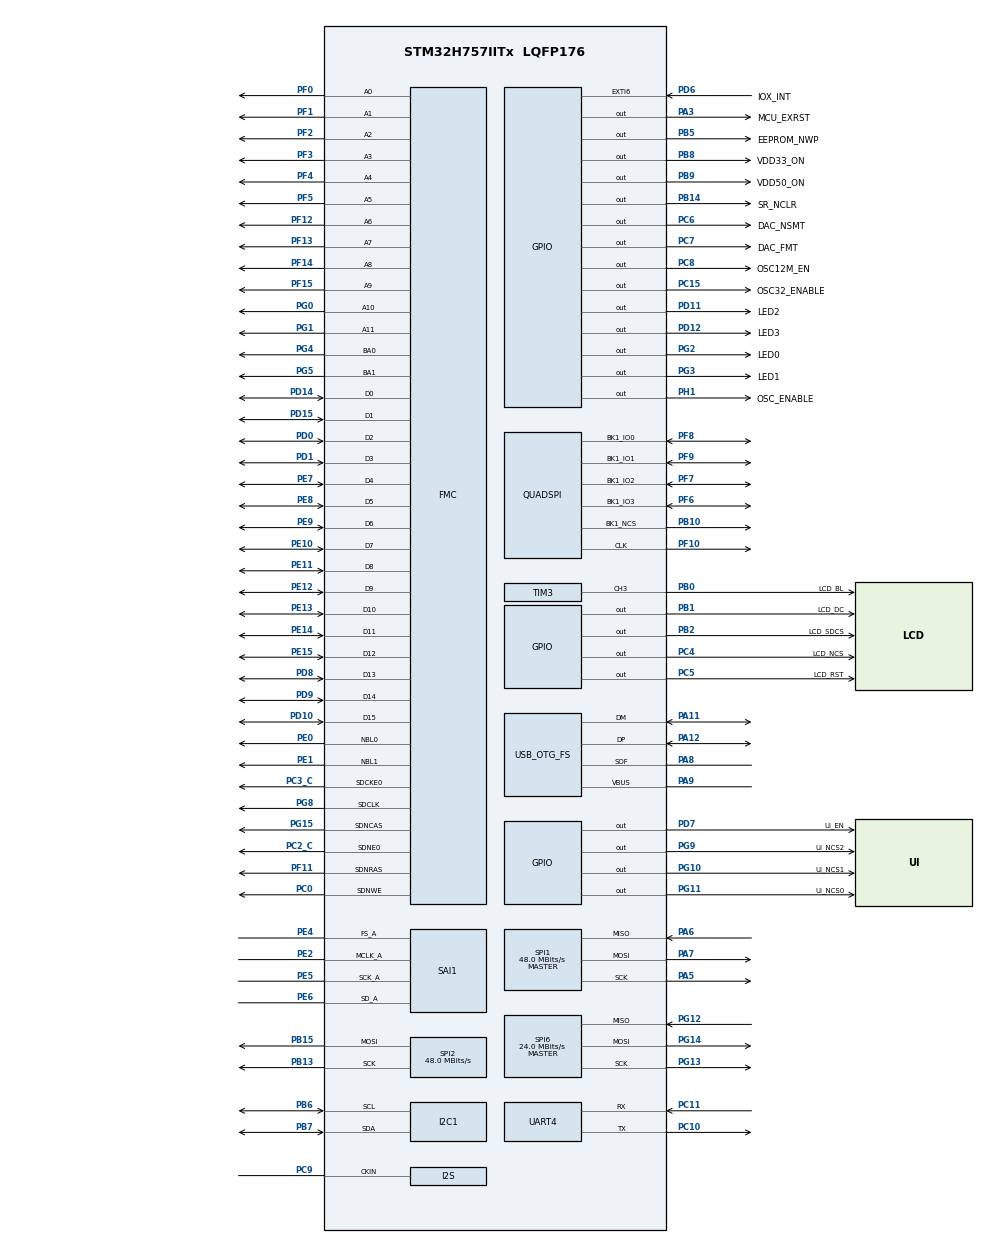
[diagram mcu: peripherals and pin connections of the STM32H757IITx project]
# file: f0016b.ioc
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CORTEX_M7.default_mode_Activation=1
CortexM4.IPs=CORTEX_M4\:I,FATFS_M4\:I,FREERTOS_M4\:I,IWDG2\:I,OPENAMP_M4\:I,PDM2PCM_M4\:I,PWR,RCC,RESMGR_UTILITY,SYS_M4\:I,USB_DEVICE_M4\:I,USB_HOST_M4\:I,VREFBUF,WWDG2\:I,GPIO,DMA,BDMA,MDMA,NVIC2\:I,DEBUG,FMC,QUADSPI
CortexM7.IPs=CORTEX_M7\:I,FATFS_M7\:I,FREERTOS_M7\:I,IWDG1\:I,OPENAMP_M7\:I,PDM2PCM_M7\:I,PWR\:I,RCC\:I,RESMGR_UTILITY\:I,SYS\:I,USB_DEVICE_M7\:I,USB_HOST_M7\:I,VREFBUF\:I,WWDG1\:I,GPIO\:I,DMA\:I,BDMA\:I,MDMA\:I,NVIC1\:I,FMC\:I,DEBUG\:I,QUADSPI\:I,USB_OTG_FS\:I,USB_OTG_FS1\:I,SPI1\:I,I2C1\:I,SAI1\:I,UART5\:I,UART4\:I,SPI6\:I,SPI2\:I,TIM3\:I
CortexM7.Pins=PC15-OSC32_OUT (OSC32_OUT),PH1-OSC_OUT (PH1),PA3,PC4,PC5,PB1,PB2,PB14,PD11,PD12,PG2,PG3,PC6,PC7,PC8,PD6,PD7,PG9,PG10,PG11,PB5,PB8,PB9
FMC.ColumnBitsNumber1=FMC_SDRAM_COLUMN_BITS_NUM_8
FMC.WriteProtection1=FMC_SDRAM_WRITE_PROTECTION_DISABLE
I2C1.Timing=0x00506682
Mcu.Family=STM32H7
Mcu.Name=STM32H757IITx
Mcu.Package=LQFP176
NVIC1.PriorityGroup=NVIC_PRIORITYGROUP_4
NVIC2.PriorityGroup=NVIC_PRIORITYGROUP_4
PA11.Mode=Device_Only
PA11.PinAttribute=CortexM7
PA11.Signal=USB_OTG_FS_DM
PA12.Mode=Device_Only
PA12.PinAttribute=CortexM7
PA12.Signal=USB_OTG_FS_DP
PA13\ (JTMS/SWDIO).Mode=Trace_Asynchronous_SW
PA13\ (JTMS/SWDIO).PinAttribute=CortexM7
PA13\ (JTMS/SWDIO).Signal=DEBUG_JTMS-SWDIO
PA14\ (JTCK/SWCLK).Mode=Trace_Asynchronous_SW
PA14\ (JTCK/SWCLK).PinAttribute=CortexM7
PA14\ (JTCK/SWCLK).Signal=DEBUG_JTCK-SWCLK
PA3.GPIO_Label=MCU_EXRST
PA3.GPIO_ModeDefaultOutputPP=GPIO_MODE_OUTPUT_OD
PA3.GPIO_PuPd=GPIO_NOPULL
PA3.PinAttribute=CortexM7
PA3.PinState=GPIO_PIN_SET
PA3.Signal=GPIO_Output
PA5.Mode=Full_Duplex_Master
PA5.PinAttribute=CortexM7
PA5.Signal=SPI1_SCK
PA6.Mode=Full_Duplex_Master
PA6.PinAttribute=CortexM7
PA6.Signal=SPI1_MISO
PA7.Mode=Full_Duplex_Master
PA7.PinAttribute=CortexM7
PA7.Signal=SPI1_MOSI
PA8.Mode=Activate_SOF_FS
PA8.PinAttribute=CortexM7
PA8.Signal=USB_OTG_FS_SOF
PA9.Mode=Activate_VBUS
PA9.PinAttribute=CortexM7
PA9.Signal=USB_OTG_FS_VBUS
PB0.GPIO_Label=LCD_BL
PB0.GPIO_ModeDefaultPP=GPIO_MODE_AF_OD
PB0.PinAttribute=CortexM7
PB0.Signal=S_TIM3_CH3
PB1.GPIO_Label=LCD_DC
PB1.PinAttribute=CortexM7
PB1.Signal=GPIO_Output
PB10.Mode=Single Bank 1
PB10.PinAttribute=CortexM7
PB10.Signal=QUADSPI_BK1_NCS
PB13.Mode=TX_Only_Simplex_Unidirect_Master
PB13.PinAttribute=CortexM7
PB13.Signal=SPI2_SCK
PB14.GPIO_Label=SR_NCLR
PB14.GPIO_ModeDefaultOutputPP=GPIO_MODE_OUTPUT_OD
PB14.GPIO_PuPd=GPIO_NOPULL
PB14.PinAttribute=CortexM7
PB14.PinState=GPIO_PIN_SET
PB14.Signal=GPIO_Output
PB15.Mode=TX_Only_Simplex_Unidirect_Master
PB15.PinAttribute=CortexM7
PB15.Signal=SPI2_MOSI
PB2.GPIO_Label=LCD_SDCS
PB2.GPIO_ModeDefaultOutputPP=GPIO_MODE_OUTPUT_OD
PB2.GPIO_PuPd=GPIO_NOPULL
PB2.PinAttribute=CortexM7
PB2.PinState=GPIO_PIN_SET
PB2.Signal=GPIO_Output
PB3\ (JTDO/TRACESWO).Mode=Trace_Asynchronous_SW
PB3\ (JTDO/TRACESWO).PinAttribute=CortexM7
PB3\ (JTDO/TRACESWO).Signal=DEBUG_JTDO-SWO
PB5.GPIO_Label=EEPROM_NWP
PB5.GPIO_ModeDefaultOutputPP=GPIO_MODE_OUTPUT_OD
PB5.GPIO_PuPd=GPIO_NOPULL
PB5.PinAttribute=CortexM7
PB5.PinState=GPIO_PIN_SET
PB5.Signal=GPIO_Output
PB6.Mode=I2C
PB6.PinAttribute=CortexM7
PB6.Signal=I2C1_SCL
PB7.Mode=I2C
PB7.PinAttribute=CortexM7
PB7.Signal=I2C1_SDA
PB8.GPIO_Label=VDD33_ON
PB8.GPIO_ModeDefaultOutputPP=GPIO_MODE_OUTPUT_OD
PB8.GPIO_PuPd=GPIO_NOPULL
PB8.PinAttribute=CortexM7
PB8.PinState=GPIO_PIN_SET
PB8.Signal=GPIO_Output
PB9.GPIO_Label=VDD50_ON
PB9.GPIO_ModeDefaultOutputPP=GPIO_MODE_OUTPUT_OD
PB9.GPIO_PuPd=GPIO_NOPULL
PB9.PinAttribute=CortexM7
PB9.PinState=GPIO_PIN_SET
PB9.Signal=GPIO_Output
PC0.PinAttribute=CortexM7
PC0.Signal=FMC_SDNWE
PC10.Mode=Asynchronous
PC10.PinAttribute=CortexM7
PC10.Signal=UART4_TX
PC11.Mode=Asynchronous
PC11.PinAttribute=CortexM7
PC11.Signal=UART4_RX
PC15-OSC32_OUT\ (OSC32_OUT).GPIO_Label=OSC32_ENABLE
PC15-OSC32_OUT\ (OSC32_OUT).GPIO_ModeDefaultOutputPP=GPIO_MODE_OUTPUT_OD
PC15-OSC32_OUT\ (OSC32_OUT).GPIO_PuPd=GPIO_NOPULL
PC15-OSC32_OUT\ (OSC32_OUT).PinAttribute=CortexM7
PC15-OSC32_OUT\ (OSC32_OUT).PinState=GPIO_PIN_SET
PC15-OSC32_OUT\ (OSC32_OUT).Signal=GPIO_Output
PC2_C.Mode=SdramChipSelect1_1
PC2_C.PinAttribute=CortexM7
PC2_C.Signal=FMC_SDNE0
PC3_C.Mode=SdramChipSelect1_1
PC3_C.PinAttribute=CortexM7
PC3_C.Signal=FMC_SDCKE0
PC4.GPIO_Label=LCD_NCS
PC4.GPIO_ModeDefaultOutputPP=GPIO_MODE_OUTPUT_OD
PC4.GPIO_PuPd=GPIO_NOPULL
PC4.PinAttribute=CortexM7
PC4.PinState=GPIO_PIN_SET
PC4.Signal=GPIO_Output
PC5.GPIO_Label=LCD_RST
PC5.GPIO_ModeDefaultOutputPP=GPIO_MODE_OUTPUT_OD
PC5.GPIO_PuPd=GPIO_NOPULL
PC5.PinAttribute=CortexM7
PC5.PinState=GPIO_PIN_SET
PC5.Signal=GPIO_Output
PC6.GPIO_Label=DAC_NSMT
PC6.PinAttribute=CortexM7
PC6.Signal=GPIO_Output
PC7.GPIO_Label=DAC_FMT
PC7.PinAttribute=CortexM7
PC7.Signal=GPIO_Output
PC8.GPIO_Label=OSC12M_EN
PC8.GPIO_ModeDefaultOutputPP=GPIO_MODE_OUTPUT_OD
PC8.GPIO_PuPd=GPIO_NOPULL
PC8.PinAttribute=CortexM7
PC8.PinState=GPIO_PIN_SET
PC8.Signal=GPIO_Output
PC9.Mode=Audio_ClockIn
PC9.PinAttribute=Free
PC9.Signal=I2S_CKIN
PD0.PinAttribute=CortexM7
PD0.Signal=FMC_D2_DA2
PD1.PinAttribute=CortexM7
PD1.Signal=FMC_D3_DA3
PD10.PinAttribute=CortexM7
PD10.Signal=FMC_D15_DA15
PD11.GPIO_Label=LED2
PD11.GPIO_ModeDefaultOutputPP=GPIO_MODE_OUTPUT_PP
PD11.GPIO_PuPd=GPIO_NOPULL
PD11.PinAttribute=CortexM7
PD11.PinState=GPIO_PIN_SET
PD11.Signal=GPIO_Output
PD12.GPIO_Label=LED3
PD12.GPIO_ModeDefaultOutputPP=GPIO_MODE_OUTPUT_PP
PD12.GPIO_PuPd=GPIO_NOPULL
PD12.PinAttribute=CortexM7
PD12.PinState=GPIO_PIN_SET
PD12.Signal=GPIO_Output
PD14.PinAttribute=CortexM7
PD14.Signal=FMC_D0_DA0
PD15.PinAttribute=CortexM7
PD15.Signal=FMC_D1_DA1
PD6.GPIO_Label=IOX_INT
PD6.PinAttribute=CortexM7
PD6.Signal=GPXTI6
PD7.GPIO_Label=UI_EN
PD7.GPIO_ModeDefaultOutputPP=GPIO_MODE_OUTPUT_OD
PD7.GPIO_PuPd=GPIO_NOPULL
PD7.PinAttribute=CortexM7
PD7.PinState=GPIO_PIN_SET
PD7.Signal=GPIO_Output
PD8.PinAttribute=CortexM7
PD8.Signal=FMC_D13_DA13
PD9.PinAttribute=CortexM7
PD9.Signal=FMC_D14_DA14
PE0.PinAttribute=CortexM7
PE0.Signal=FMC_NBL0
PE1.PinAttribute=CortexM7
PE1.Signal=FMC_NBL1
PE10.PinAttribute=CortexM7
PE10.Signal=FMC_D7_DA7
PE11.PinAttribute=CortexM7
PE11.Signal=FMC_D8_DA8
PE12.PinAttribute=CortexM7
PE12.Signal=FMC_D9_DA9
PE13.PinAttribute=CortexM7
PE13.Signal=FMC_D10_DA10
PE14.PinAttribute=CortexM7
PE14.Signal=FMC_D11_DA11
PE15.PinAttribute=CortexM7
PE15.Signal=FMC_D12_DA12
PE2.Mode=SAI_A_MasterWithClock
PE2.PinAttribute=CortexM7
PE2.Signal=SAI1_MCLK_A
PE4.Mode=SAI_A_MasterWithClock
PE4.PinAttribute=CortexM7
PE4.Signal=SAI1_FS_A
PE5.Mode=SAI_A_MasterWithClock
PE5.PinAttribute=CortexM7
PE5.Signal=SAI1_SCK_A
PE6.Mode=SAI_A_MasterWithClock
PE6.PinAttribute=CortexM7
PE6.Signal=SAI1_SD_A
PE7.PinAttribute=CortexM7
PE7.Signal=FMC_D4_DA4
PE8.PinAttribute=CortexM7
PE8.Signal=FMC_D5_DA5
PE9.PinAttribute=CortexM7
PE9.Signal=FMC_D6_DA6
PF0.PinAttribute=CortexM7
PF0.Signal=FMC_A0
PF1.PinAttribute=CortexM7
PF1.Signal=FMC_A1
PF10.Mode=Single Bank 1
PF10.PinAttribute=CortexM7
PF10.Signal=QUADSPI_CLK
PF11.PinAttribute=CortexM7
PF11.Signal=FMC_SDNRAS
PF12.PinAttribute=CortexM7
PF12.Signal=FMC_A6
PF13.PinAttribute=CortexM7
PF13.Signal=FMC_A7
PF14.PinAttribute=CortexM7
PF14.Signal=FMC_A8
PF15.PinAttribute=CortexM7
PF15.Signal=FMC_A9
PF2.PinAttribute=CortexM7
PF2.Signal=FMC_A2
PF3.PinAttribute=CortexM7
PF3.Signal=FMC_A3
PF4.PinAttribute=CortexM7
PF4.Signal=FMC_A4
PF5.PinAttribute=CortexM7
PF5.Signal=FMC_A5
PF6.Mode=Single Bank 1
PF6.PinAttribute=CortexM7
PF6.Signal=QUADSPI_BK1_IO3
PF7.Mode=Single Bank 1
PF7.PinAttribute=CortexM7
PF7.Signal=QUADSPI_BK1_IO2
PF8.Mode=Single Bank 1
PF8.PinAttribute=CortexM7
PF8.Signal=QUADSPI_BK1_IO0
PF9.Mode=Single Bank 1
PF9.PinAttribute=CortexM7
PF9.Signal=QUADSPI_BK1_IO1
PG0.PinAttribute=CortexM7
PG0.Signal=FMC_A10
PG1.PinAttribute=CortexM7
PG1.Signal=FMC_A11
PG10.GPIO_Label=UI_NCS1
PG10.GPIO_ModeDefaultOutputPP=GPIO_MODE_OUTPUT_OD
PG10.GPIO_PuPd=GPIO_NOPULL
PG10.PinAttribute=CortexM7
PG10.PinState=GPIO_PIN_SET
PG10.Signal=GPIO_Output
PG11.GPIO_Label=UI_NCS0
PG11.GPIO_ModeDefaultOutputPP=GPIO_MODE_OUTPUT_OD
PG11.GPIO_PuPd=GPIO_NOPULL
PG11.PinAttribute=CortexM7
PG11.PinState=GPIO_PIN_SET
PG11.Signal=GPIO_Output
PG12.Mode=Full_Duplex_Master
PG12.PinAttribute=CortexM7
PG12.Signal=SPI6_MISO
PG13.Mode=Full_Duplex_Master
PG13.PinAttribute=CortexM7
PG13.Signal=SPI6_SCK
PG14.Mode=Full_Duplex_Master
PG14.PinAttribute=CortexM7
PG14.Signal=SPI6_MOSI
PG15.PinAttribute=CortexM7
PG15.Signal=FMC_SDNCAS
PG2.GPIO_Label=LED0
PG2.GPIO_ModeDefaultOutputPP=GPIO_MODE_OUTPUT_PP
PG2.GPIO_PuPd=GPIO_NOPULL
PG2.PinAttribute=CortexM7
PG2.PinState=GPIO_PIN_SET
PG2.Signal=GPIO_Output
PG3.GPIO_Label=LED1
PG3.GPIO_ModeDefaultOutputPP=GPIO_MODE_OUTPUT_PP
PG3.GPIO_PuPd=GPIO_NOPULL
PG3.PinAttribute=CortexM7
PG3.PinState=GPIO_PIN_SET
PG3.Signal=GPIO_Output
PG4.PinAttribute=CortexM7
PG4.Signal=FMC_A14_BA0
PG5.PinAttribute=CortexM7
PG5.Signal=FMC_A15_BA1
PG8.PinAttribute=CortexM7
PG8.Signal=FMC_SDCLK
PG9.GPIO_Label=UI_NCS2
PG9.GPIO_ModeDefaultOutputPP=GPIO_MODE_OUTPUT_OD
PG9.GPIO_PuPd=GPIO_NOPULL
PG9.PinAttribute=CortexM7
PG9.PinState=GPIO_PIN_SET
PG9.Signal=GPIO_Output
PH0-OSC_IN\ (PH0).Mode=HSE-External-Clock-Source
PH0-OSC_IN\ (PH0).PinAttribute=Free
PH0-OSC_IN\ (PH0).Signal=RCC_OSC_IN
PH1-OSC_OUT\ (PH1).GPIO_Label=OSC_ENABLE
PH1-OSC_OUT\ (PH1).GPIO_ModeDefaultOutputPP=GPIO_MODE_OUTPUT_OD
PH1-OSC_OUT\ (PH1).GPIO_PuPd=GPIO_NOPULL
PH1-OSC_OUT\ (PH1).PinAttribute=CortexM7
PH1-OSC_OUT\ (PH1).PinState=GPIO_PIN_SET
PH1-OSC_OUT\ (PH1).Signal=GPIO_Output
ProjectManager.HeapSize=M4-0x200,M7-0x200
ProjectManager.StackSize=M4-0x400,M7-0x400
ProjectManager.TargetToolchain=STM32CubeIDE
RCC.ADCFreq_Value=180000000
RCC.APB1Freq_Value=100000000
RCC.APB2Freq_Value=100000000
RCC.APB3Freq_Value=100000000
RCC.APB4Freq_Value=100000000
RCC.CortexFreq_Value=400000000
RCC.D1PPRE=RCC_APB3_DIV2
RCC.D2PPRE1=RCC_APB1_DIV2
RCC.D2PPRE2=RCC_APB2_DIV2
RCC.D3PPRE=RCC_APB4_DIV2
RCC.DIVM1=5
RCC.DIVM2=5
RCC.DIVM3=25
RCC.DIVN1=160
RCC.DIVN2=36
RCC.DIVN3=192
RCC.DIVP2=1
RCC.DIVQ1=8
RCC.DIVQ3=4
RCC.DIVR1=25
RCC.DIVR2=1
RCC.DIVR3=8
RCC.FMCCLockSelection=RCC_FMCCLKSOURCE_PLL
RCC.HCLKFreq_Value=200000000
RCC.HPRE=RCC_HCLK_DIV2
RCC.I2C123CLockSelection=RCC_I2C123CLKSOURCE_PLL3
RCC.QSPICLockSelection=RCC_QSPICLKSOURCE_PLL
RCC.SAI1CLockSelection=RCC_SAI1CLKSOURCE_PIN
RCC.SPI123CLockSelection=RCC_SPI123CLKSOURCE_PLL3
RCC.SPI6CLockSelection=RCC_SPI6CLKSOURCE_PLL3
RCC.SYSCLKFreq_VALUE=400000000
RCC.SYSCLKSource=RCC_SYSCLKSOURCE_PLLCLK
RCC.USART234578CLockSelection=RCC_USART234578CLKSOURCE_PLL3
RCC.USBCLockSelection=RCC_USBCLKSOURCE_PLL3
RCC.USBFreq_Value=48000000
SAI1.ErrorAudioFreq-SAI_A_MasterWithClock=-75.0 %
SAI1.InitProtocol-SAI_A_MasterWithClock=Enable
SAI1.Instance-SAI_A_MasterWithClock=SAI$Index_Block_A
SAI1.MClockEnable-SAI_A_MasterWithClock=SAI_MASTERCLOCK_ENABLE
SAI1.RealAudioFreq-SAI_A_MasterWithClock=48.0 KHz
SAI1.VirtualMode-SAI_A_MasterWithClock=VM_MASTER
SAI1.VirtualProtocol-SAI_A_BASIC=VM_BASIC_PROTOCOL
SH.FMC_A0.0=FMC_A0,12b-sda1
SH.FMC_A1.0=FMC_A1,12b-sda1
SH.FMC_A10.0=FMC_A10,12b-sda1
SH.FMC_A11.0=FMC_A11,12b-sda1
SH.FMC_A14_BA0.0=FMC_BA0,FourSdramBanks1
SH.FMC_A15_BA1.0=FMC_BA1,FourSdramBanks1
SH.FMC_A2.0=FMC_A2,12b-sda1
SH.FMC_A3.0=FMC_A3,12b-sda1
SH.FMC_A4.0=FMC_A4,12b-sda1
SH.FMC_A5.0=FMC_A5,12b-sda1
SH.FMC_A6.0=FMC_A6,12b-sda1
SH.FMC_A7.0=FMC_A7,12b-sda1
SH.FMC_A8.0=FMC_A8,12b-sda1
SH.FMC_A9.0=FMC_A9,12b-sda1
SH.FMC_D0_DA0.0=FMC_D0,sd-16b-d1
SH.FMC_D10_DA10.0=FMC_D10,sd-16b-d1
SH.FMC_D11_DA11.0=FMC_D11,sd-16b-d1
SH.FMC_D12_DA12.0=FMC_D12,sd-16b-d1
SH.FMC_D13_DA13.0=FMC_D13,sd-16b-d1
SH.FMC_D14_DA14.0=FMC_D14,sd-16b-d1
SH.FMC_D15_DA15.0=FMC_D15,sd-16b-d1
SH.FMC_D1_DA1.0=FMC_D1,sd-16b-d1
SH.FMC_D2_DA2.0=FMC_D2,sd-16b-d1
SH.FMC_D3_DA3.0=FMC_D3,sd-16b-d1
SH.FMC_D4_DA4.0=FMC_D4,sd-16b-d1
SH.FMC_D5_DA5.0=FMC_D5,sd-16b-d1
SH.FMC_D6_DA6.0=FMC_D6,sd-16b-d1
SH.FMC_D7_DA7.0=FMC_D7,sd-16b-d1
SH.FMC_D8_DA8.0=FMC_D8,sd-16b-d1
SH.FMC_D9_DA9.0=FMC_D9,sd-16b-d1
SH.FMC_NBL0.0=FMC_NBL0,Sd2ByteEnable1
SH.FMC_NBL1.0=FMC_NBL1,Sd2ByteEnable1
SH.FMC_SDCLK.0=FMC_SDCLK,12b-sda1
SH.FMC_SDNCAS.0=FMC_SDNCAS,12b-sda1
SH.FMC_SDNRAS.0=FMC_SDNRAS,12b-sda1
SH.FMC_SDNWE.0=FMC_SDNWE,12b-sda1
SH.S_TIM3_CH3.0=TIM3_CH3,PWM Generation3 CH3
SPI1.BaudRatePrescaler=SPI_BAUDRATEPRESCALER_2
SPI1.CalculateBaudRate=48.0 MBits/s
SPI1.Direction=SPI_DIRECTION_2LINES
SPI1.Mode=SPI_MODE_MASTER
SPI1.VirtualType=VM_MASTER
SPI2.CalculateBaudRate=48.0 MBits/s
SPI2.Direction=SPI_DIRECTION_2LINES_TXONLY
SPI2.Mode=SPI_MODE_MASTER
SPI2.VirtualType=VM_MASTER
SPI6.BaudRatePrescaler=SPI_BAUDRATEPRESCALER_2
SPI6.CalculateBaudRate=24.0 MBits/s
SPI6.Direction=SPI_DIRECTION_2LINES
SPI6.Mode=SPI_MODE_MASTER
SPI6.VirtualType=VM_MASTER
SYS.userName=SYS_M7
TIM3.Channel-PWM\ Generation3\ CH3=TIM_CHANNEL_3
USB_OTG_FS.VirtualMode=Device_Only
VP_SAI1_VP_$IpInstance_SAIA_SAI_BASIC.Mode=SAI_A_BASIC
VP_SYS_M4_VS_Systick.Mode=SysTick
board=custom

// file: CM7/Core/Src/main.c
/* USER CODE BEGIN Header */
/**
  ******************************************************************************
  * @file           : main.c
  * @brief          : Main program body
  ******************************************************************************
  * @attention
  *
  * Copyright (c) 2026 STMicroelectronics.
  * All rights reserved.
  *
  * This software is licensed under terms that can be found in the LICENSE file
  * in the root directory of this software component.
  * If no LICENSE file comes with this software, it is provided AS-IS.
  *
  ******************************************************************************
  */
/* USER CODE END Header */
#include "main.h"

/* USER CODE BEGIN PD */

/* DUAL_CORE_BOOT_SYNC_SEQUENCE: Define for dual core boot synchronization    */
/*                             demonstration code based on hardware semaphore */
/* This define is present in both CM7/CM4 projects                            */
/* To comment when developping/debugging on a single core                     */
#define DUAL_CORE_BOOT_SYNC_SEQUENCE

#if defined(DUAL_CORE_BOOT_SYNC_SEQUENCE)
#ifndef HSEM_ID_0
#define HSEM_ID_0 (0U) /* HW semaphore 0*/
#endif
#endif /* DUAL_CORE_BOOT_SYNC_SEQUENCE */

/* USER CODE END PD */

I2C_HandleTypeDef hi2c1;

QSPI_HandleTypeDef hqspi;

SAI_HandleTypeDef hsai_BlockA1;

SPI_HandleTypeDef hspi1;
SPI_HandleTypeDef hspi2;
SPI_HandleTypeDef hspi6;

TIM_HandleTypeDef htim3;

UART_HandleTypeDef huart4;

PCD_HandleTypeDef hpcd_USB_OTG_FS;

SDRAM_HandleTypeDef hsdram1;

void SystemClock_Config(void);
void PeriphCommonClock_Config(void);
static void MPU_Config(void);
static void MX_GPIO_Init(void);
static void MX_FMC_Init(void);
static void MX_I2C1_Init(void);
static void MX_QUADSPI_Init(void);
static void MX_SAI1_Init(void);
static void MX_SPI1_Init(void);
static void MX_SPI6_Init(void);
static void MX_UART4_Init(void);
static void MX_USB_OTG_FS_PCD_Init(void);
static void MX_SPI2_Init(void);
static void MX_TIM3_Init(void);

int main(void)
{

/* USER CODE BEGIN Boot_Mode_Sequence_0 */
#if defined(DUAL_CORE_BOOT_SYNC_SEQUENCE)
  int32_t timeout;
#endif /* DUAL_CORE_BOOT_SYNC_SEQUENCE */
/* USER CODE END Boot_Mode_Sequence_0 */

  /* MPU Configuration--------------------------------------------------------*/
  MPU_Config();

/* USER CODE BEGIN Boot_Mode_Sequence_1 */
#if defined(DUAL_CORE_BOOT_SYNC_SEQUENCE)
  /* Wait until CPU2 boots and enters in stop mode or timeout*/
  timeout = 0xFFFF;
  while((__HAL_RCC_GET_FLAG(RCC_FLAG_D2CKRDY) != RESET) && (timeout-- > 0));
  if ( timeout < 0 )
  {
  Error_Handler();
  }
#endif /* DUAL_CORE_BOOT_SYNC_SEQUENCE */
/* USER CODE END Boot_Mode_Sequence_1 */
  /* MCU Configuration--------------------------------------------------------*/

  /* Reset of all peripherals, Initializes the Flash interface and the Systick. */
  HAL_Init();

  /* Configure the system clock */
  SystemClock_Config();

  /* Configure the peripherals common clocks */
  PeriphCommonClock_Config();
/* USER CODE BEGIN Boot_Mode_Sequence_2 */
#if defined(DUAL_CORE_BOOT_SYNC_SEQUENCE)
/* When system initialization is finished, Cortex-M7 will release Cortex-M4 by means of
HSEM notification */
/*HW semaphore Clock enable*/
__HAL_RCC_HSEM_CLK_ENABLE();
/*Take HSEM */
HAL_HSEM_FastTake(HSEM_ID_0);
/*Release HSEM in order to notify the CPU2(CM4)*/
HAL_HSEM_Release(HSEM_ID_0,0);
/* wait until CPU2 wakes up from stop mode */
timeout = 0xFFFF;
while((__HAL_RCC_GET_FLAG(RCC_FLAG_D2CKRDY) == RESET) && (timeout-- > 0));
if ( timeout < 0 )
{
Error_Handler();
}
#endif /* DUAL_CORE_BOOT_SYNC_SEQUENCE */
/* USER CODE END Boot_Mode_Sequence_2 */

  /* Initialize all configured peripherals */
  MX_GPIO_Init();
  MX_FMC_Init();
  MX_I2C1_Init();
  MX_QUADSPI_Init();
  MX_SAI1_Init();
  MX_SPI1_Init();
  MX_SPI6_Init();
  MX_UART4_Init();
  MX_USB_OTG_FS_PCD_Init();
  MX_SPI2_Init();
  MX_TIM3_Init();
  /* USER CODE BEGIN 2 */
  HAL_GPIO_WritePin(LED0_GPIO_Port, LED0_Pin, GPIO_PIN_SET);
  HAL_GPIO_WritePin(LED1_GPIO_Port, LED1_Pin, GPIO_PIN_SET);
  HAL_GPIO_WritePin(LED2_GPIO_Port, LED2_Pin, GPIO_PIN_SET);
  HAL_GPIO_WritePin(LED3_GPIO_Port, LED3_Pin, GPIO_PIN_SET);
  HAL_Delay(3000);
  for (int i = 0; i < 10; i++) {
    HAL_GPIO_TogglePin(LED0_GPIO_Port, LED0_Pin);
    HAL_GPIO_TogglePin(LED1_GPIO_Port, LED1_Pin);
    HAL_GPIO_TogglePin(LED2_GPIO_Port, LED2_Pin);
    HAL_GPIO_TogglePin(LED3_GPIO_Port, LED3_Pin);
    HAL_Delay(100);
  }
  /* USER CODE END 2 */

  /* Infinite loop */
  /* USER CODE BEGIN WHILE */
  while (1)
  {
    HAL_GPIO_TogglePin(LED0_GPIO_Port, LED0_Pin);
    HAL_GPIO_TogglePin(LED1_GPIO_Port, LED1_Pin);
    HAL_GPIO_TogglePin(LED2_GPIO_Port, LED2_Pin);
    HAL_GPIO_TogglePin(LED3_GPIO_Port, LED3_Pin);
    HAL_Delay(1000);
    /* USER CODE END WHILE */

  }
}

void SystemClock_Config(void)
{
  RCC_OscInitTypeDef RCC_OscInitStruct = {0};
  RCC_ClkInitTypeDef RCC_ClkInitStruct = {0};

  /** Supply configuration update enable
  */
  HAL_PWREx_ConfigSupply(PWR_DIRECT_SMPS_SUPPLY);

  /** Configure the main internal regulator output voltage
  */
  __HAL_PWR_VOLTAGESCALING_CONFIG(PWR_REGULATOR_VOLTAGE_SCALE1);

  while(!__HAL_PWR_GET_FLAG(PWR_FLAG_VOSRDY)) {}

  /** Initializes the RCC Oscillators according to the specified parameters
  * in the RCC_OscInitTypeDef structure.
  */
  RCC_OscInitStruct.OscillatorType = RCC_OSCILLATORTYPE_HSE;
  RCC_OscInitStruct.HSEState = RCC_HSE_BYPASS;
  RCC_OscInitStruct.PLL.PLLState = RCC_PLL_ON;
  RCC_OscInitStruct.PLL.PLLSource = RCC_PLLSOURCE_HSE;
  RCC_OscInitStruct.PLL.PLLM = 5;
  RCC_OscInitStruct.PLL.PLLN = 160;
  RCC_OscInitStruct.PLL.PLLP = 2;
  RCC_OscInitStruct.PLL.PLLQ = 8;
  RCC_OscInitStruct.PLL.PLLR = 25;
  RCC_OscInitStruct.PLL.PLLRGE = RCC_PLL1VCIRANGE_2;
  RCC_OscInitStruct.PLL.PLLVCOSEL = RCC_PLL1VCOWIDE;
  RCC_OscInitStruct.PLL.PLLFRACN = 0;
  if (HAL_RCC_OscConfig(&RCC_OscInitStruct) != HAL_OK)
  {
    Error_Handler();
  }

  /** Initializes the CPU, AHB and APB buses clocks
  */
  RCC_ClkInitStruct.ClockType = RCC_CLOCKTYPE_HCLK|RCC_CLOCKTYPE_SYSCLK
                              |RCC_CLOCKTYPE_PCLK1|RCC_CLOCKTYPE_PCLK2
                              |RCC_CLOCKTYPE_D3PCLK1|RCC_CLOCKTYPE_D1PCLK1;
  RCC_ClkInitStruct.SYSCLKSource = RCC_SYSCLKSOURCE_PLLCLK;
  RCC_ClkInitStruct.SYSCLKDivider = RCC_SYSCLK_DIV1;
  RCC_ClkInitStruct.AHBCLKDivider = RCC_HCLK_DIV2;
  RCC_ClkInitStruct.APB3CLKDivider = RCC_APB3_DIV2;
  RCC_ClkInitStruct.APB1CLKDivider = RCC_APB1_DIV2;
  RCC_ClkInitStruct.APB2CLKDivider = RCC_APB2_DIV2;
  RCC_ClkInitStruct.APB4CLKDivider = RCC_APB4_DIV2;

  if (HAL_RCC_ClockConfig(&RCC_ClkInitStruct, FLASH_LATENCY_2) != HAL_OK)
  {
    Error_Handler();
  }
}

void PeriphCommonClock_Config(void)
{
  RCC_PeriphCLKInitTypeDef PeriphClkInitStruct = {0};

  /** Initializes the peripherals clock
  */
  PeriphClkInitStruct.PeriphClockSelection = RCC_PERIPHCLK_USB|RCC_PERIPHCLK_SPI6
                              |RCC_PERIPHCLK_I2C1|RCC_PERIPHCLK_SPI2
                              |RCC_PERIPHCLK_SPI1|RCC_PERIPHCLK_UART4;
  PeriphClkInitStruct.PLL3.PLL3M = 25;
  PeriphClkInitStruct.PLL3.PLL3N = 192;
  PeriphClkInitStruct.PLL3.PLL3P = 2;
  PeriphClkInitStruct.PLL3.PLL3Q = 4;
  PeriphClkInitStruct.PLL3.PLL3R = 8;
  PeriphClkInitStruct.PLL3.PLL3RGE = RCC_PLL3VCIRANGE_0;
  PeriphClkInitStruct.PLL3.PLL3VCOSEL = RCC_PLL3VCOWIDE;
  PeriphClkInitStruct.PLL3.PLL3FRACN = 0;
  PeriphClkInitStruct.Spi123ClockSelection = RCC_SPI123CLKSOURCE_PLL3;
  PeriphClkInitStruct.Usart234578ClockSelection = RCC_USART234578CLKSOURCE_PLL3;
  PeriphClkInitStruct.I2c123ClockSelection = RCC_I2C123CLKSOURCE_PLL3;
  PeriphClkInitStruct.UsbClockSelection = RCC_USBCLKSOURCE_PLL3;
  PeriphClkInitStruct.Spi6ClockSelection = RCC_SPI6CLKSOURCE_PLL3;
  if (HAL_RCCEx_PeriphCLKConfig(&PeriphClkInitStruct) != HAL_OK)
  {
    Error_Handler();
  }
}

static void MX_I2C1_Init(void)
{

  hi2c1.Instance = I2C1;
  hi2c1.Init.Timing = 0x00506682;
  hi2c1.Init.OwnAddress1 = 0;
  hi2c1.Init.AddressingMode = I2C_ADDRESSINGMODE_7BIT;
  hi2c1.Init.DualAddressMode = I2C_DUALADDRESS_DISABLE;
  hi2c1.Init.OwnAddress2 = 0;
  hi2c1.Init.OwnAddress2Masks = I2C_OA2_NOMASK;
  hi2c1.Init.GeneralCallMode = I2C_GENERALCALL_DISABLE;
  hi2c1.Init.NoStretchMode = I2C_NOSTRETCH_DISABLE;
  if (HAL_I2C_Init(&hi2c1) != HAL_OK)
  {
    Error_Handler();
  }

  /** Configure Analogue filter
  */
  if (HAL_I2CEx_ConfigAnalogFilter(&hi2c1, I2C_ANALOGFILTER_ENABLE) != HAL_OK)
  {
    Error_Handler();
  }

  /** Configure Digital filter
  */
  if (HAL_I2CEx_ConfigDigitalFilter(&hi2c1, 0) != HAL_OK)
  {
    Error_Handler();
  }

}

static void MX_QUADSPI_Init(void)
{

  /* QUADSPI parameter configuration*/
  hqspi.Instance = QUADSPI;
  hqspi.Init.ClockPrescaler = 255;
  hqspi.Init.FifoThreshold = 1;
  hqspi.Init.SampleShifting = QSPI_SAMPLE_SHIFTING_NONE;
  hqspi.Init.FlashSize = 1;
  hqspi.Init.ChipSelectHighTime = QSPI_CS_HIGH_TIME_1_CYCLE;
  hqspi.Init.ClockMode = QSPI_CLOCK_MODE_0;
  hqspi.Init.FlashID = QSPI_FLASH_ID_1;
  hqspi.Init.DualFlash = QSPI_DUALFLASH_DISABLE;
  if (HAL_QSPI_Init(&hqspi) != HAL_OK)
  {
    Error_Handler();
  }

}

static void MX_SAI1_Init(void)
{

  hsai_BlockA1.Instance = SAI1_Block_A;
  hsai_BlockA1.Init.AudioMode = SAI_MODEMASTER_TX;
  hsai_BlockA1.Init.Synchro = SAI_ASYNCHRONOUS;
  hsai_BlockA1.Init.OutputDrive = SAI_OUTPUTDRIVE_DISABLE;
  hsai_BlockA1.Init.NoDivider = SAI_MASTERDIVIDER_ENABLE;
  hsai_BlockA1.Init.MckOverSampling = SAI_MCK_OVERSAMPLING_DISABLE;
  hsai_BlockA1.Init.FIFOThreshold = SAI_FIFOTHRESHOLD_EMPTY;
  hsai_BlockA1.Init.AudioFrequency = SAI_AUDIO_FREQUENCY_192K;
  hsai_BlockA1.Init.SynchroExt = SAI_SYNCEXT_DISABLE;
  hsai_BlockA1.Init.MonoStereoMode = SAI_STEREOMODE;
  hsai_BlockA1.Init.CompandingMode = SAI_NOCOMPANDING;
  hsai_BlockA1.Init.TriState = SAI_OUTPUT_NOTRELEASED;
  if (HAL_SAI_InitProtocol(&hsai_BlockA1, SAI_I2S_STANDARD, SAI_PROTOCOL_DATASIZE_16BIT, 2) != HAL_OK)
  {
    Error_Handler();
  }

}

static void MX_SPI1_Init(void)
{

  /* SPI1 parameter configuration*/
  hspi1.Instance = SPI1;
  hspi1.Init.Mode = SPI_MODE_MASTER;
  hspi1.Init.Direction = SPI_DIRECTION_2LINES;
  hspi1.Init.DataSize = SPI_DATASIZE_4BIT;
  hspi1.Init.CLKPolarity = SPI_POLARITY_LOW;
  hspi1.Init.CLKPhase = SPI_PHASE_1EDGE;
  hspi1.Init.NSS = SPI_NSS_SOFT;
  hspi1.Init.BaudRatePrescaler = SPI_BAUDRATEPRESCALER_2;
  hspi1.Init.FirstBit = SPI_FIRSTBIT_MSB;
  hspi1.Init.TIMode = SPI_TIMODE_DISABLE;
  hspi1.Init.CRCCalculation = SPI_CRCCALCULATION_DISABLE;
  hspi1.Init.CRCPolynomial = 0x0;
  hspi1.Init.NSSPMode = SPI_NSS_PULSE_ENABLE;
  hspi1.Init.NSSPolarity = SPI_NSS_POLARITY_LOW;
  hspi1.Init.FifoThreshold = SPI_FIFO_THRESHOLD_01DATA;
  hspi1.Init.TxCRCInitializationPattern = SPI_CRC_INITIALIZATION_ALL_ZERO_PATTERN;
  hspi1.Init.RxCRCInitializationPattern = SPI_CRC_INITIALIZATION_ALL_ZERO_PATTERN;
  hspi1.Init.MasterSSIdleness = SPI_MASTER_SS_IDLENESS_00CYCLE;
  hspi1.Init.MasterInterDataIdleness = SPI_MASTER_INTERDATA_IDLENESS_00CYCLE;
  hspi1.Init.MasterReceiverAutoSusp = SPI_MASTER_RX_AUTOSUSP_DISABLE;
  hspi1.Init.MasterKeepIOState = SPI_MASTER_KEEP_IO_STATE_DISABLE;
  hspi1.Init.IOSwap = SPI_IO_SWAP_DISABLE;
  if (HAL_SPI_Init(&hspi1) != HAL_OK)
  {
    Error_Handler();
  }

}

static void MX_SPI2_Init(void)
{

  /* SPI2 parameter configuration*/
  hspi2.Instance = SPI2;
  hspi2.Init.Mode = SPI_MODE_MASTER;
  hspi2.Init.Direction = SPI_DIRECTION_2LINES_TXONLY;
  hspi2.Init.DataSize = SPI_DATASIZE_4BIT;
  hspi2.Init.CLKPolarity = SPI_POLARITY_LOW;
  hspi2.Init.CLKPhase = SPI_PHASE_1EDGE;
  hspi2.Init.NSS = SPI_NSS_SOFT;
  hspi2.Init.BaudRatePrescaler = SPI_BAUDRATEPRESCALER_2;
  hspi2.Init.FirstBit = SPI_FIRSTBIT_MSB;
  hspi2.Init.TIMode = SPI_TIMODE_DISABLE;
  hspi2.Init.CRCCalculation = SPI_CRCCALCULATION_DISABLE;
  hspi2.Init.CRCPolynomial = 0x0;
  hspi2.Init.NSSPMode = SPI_NSS_PULSE_ENABLE;
  hspi2.Init.NSSPolarity = SPI_NSS_POLARITY_LOW;
  hspi2.Init.FifoThreshold = SPI_FIFO_THRESHOLD_01DATA;
  hspi2.Init.TxCRCInitializationPattern = SPI_CRC_INITIALIZATION_ALL_ZERO_PATTERN;
  hspi2.Init.RxCRCInitializationPattern = SPI_CRC_INITIALIZATION_ALL_ZERO_PATTERN;
  hspi2.Init.MasterSSIdleness = SPI_MASTER_SS_IDLENESS_00CYCLE;
  hspi2.Init.MasterInterDataIdleness = SPI_MASTER_INTERDATA_IDLENESS_00CYCLE;
  hspi2.Init.MasterReceiverAutoSusp = SPI_MASTER_RX_AUTOSUSP_DISABLE;
  hspi2.Init.MasterKeepIOState = SPI_MASTER_KEEP_IO_STATE_DISABLE;
  hspi2.Init.IOSwap = SPI_IO_SWAP_DISABLE;
  if (HAL_SPI_Init(&hspi2) != HAL_OK)
  {
    Error_Handler();
  }

}

static void MX_SPI6_Init(void)
{

  /* SPI6 parameter configuration*/
  hspi6.Instance = SPI6;
  hspi6.Init.Mode = SPI_MODE_MASTER;
  hspi6.Init.Direction = SPI_DIRECTION_2LINES;
  hspi6.Init.DataSize = SPI_DATASIZE_4BIT;
  hspi6.Init.CLKPolarity = SPI_POLARITY_LOW;
  hspi6.Init.CLKPhase = SPI_PHASE_1EDGE;
  hspi6.Init.NSS = SPI_NSS_SOFT;
  hspi6.Init.BaudRatePrescaler = SPI_BAUDRATEPRESCALER_2;
  hspi6.Init.FirstBit = SPI_FIRSTBIT_MSB;
  hspi6.Init.TIMode = SPI_TIMODE_DISABLE;
  hspi6.Init.CRCCalculation = SPI_CRCCALCULATION_DISABLE;
  hspi6.Init.CRCPolynomial = 0x0;
  hspi6.Init.NSSPMode = SPI_NSS_PULSE_ENABLE;
  hspi6.Init.NSSPolarity = SPI_NSS_POLARITY_LOW;
  hspi6.Init.FifoThreshold = SPI_FIFO_THRESHOLD_01DATA;
  hspi6.Init.TxCRCInitializationPattern = SPI_CRC_INITIALIZATION_ALL_ZERO_PATTERN;
  hspi6.Init.RxCRCInitializationPattern = SPI_CRC_INITIALIZATION_ALL_ZERO_PATTERN;
  hspi6.Init.MasterSSIdleness = SPI_MASTER_SS_IDLENESS_00CYCLE;
  hspi6.Init.MasterInterDataIdleness = SPI_MASTER_INTERDATA_IDLENESS_00CYCLE;
  hspi6.Init.MasterReceiverAutoSusp = SPI_MASTER_RX_AUTOSUSP_DISABLE;
  hspi6.Init.MasterKeepIOState = SPI_MASTER_KEEP_IO_STATE_DISABLE;
  hspi6.Init.IOSwap = SPI_IO_SWAP_DISABLE;
  if (HAL_SPI_Init(&hspi6) != HAL_OK)
  {
    Error_Handler();
  }

}

static void MX_TIM3_Init(void)
{

  TIM_MasterConfigTypeDef sMasterConfig = {0};
  TIM_OC_InitTypeDef sConfigOC = {0};

  htim3.Instance = TIM3;
  htim3.Init.Prescaler = 0;
  htim3.Init.CounterMode = TIM_COUNTERMODE_UP;
  htim3.Init.Period = 65535;
  htim3.Init.ClockDivision = TIM_CLOCKDIVISION_DIV1;
  htim3.Init.AutoReloadPreload = TIM_AUTORELOAD_PRELOAD_DISABLE;
  if (HAL_TIM_PWM_Init(&htim3) != HAL_OK)
  {
    Error_Handler();
  }
  sMasterConfig.MasterOutputTrigger = TIM_TRGO_RESET;
  sMasterConfig.MasterSlaveMode = TIM_MASTERSLAVEMODE_DISABLE;
  if (HAL_TIMEx_MasterConfigSynchronization(&htim3, &sMasterConfig) != HAL_OK)
  {
    Error_Handler();
  }
  sConfigOC.OCMode = TIM_OCMODE_PWM1;
  sConfigOC.Pulse = 0;
  sConfigOC.OCPolarity = TIM_OCPOLARITY_HIGH;
  sConfigOC.OCFastMode = TIM_OCFAST_DISABLE;
  if (HAL_TIM_PWM_ConfigChannel(&htim3, &sConfigOC, TIM_CHANNEL_3) != HAL_OK)
  {
    Error_Handler();
  }
  HAL_TIM_MspPostInit(&htim3);

}

static void MX_UART4_Init(void)
{

  huart4.Instance = UART4;
  huart4.Init.BaudRate = 115200;
  huart4.Init.WordLength = UART_WORDLENGTH_8B;
  huart4.Init.StopBits = UART_STOPBITS_1;
  huart4.Init.Parity = UART_PARITY_NONE;
  huart4.Init.Mode = UART_MODE_TX_RX;
  huart4.Init.HwFlowCtl = UART_HWCONTROL_NONE;
  huart4.Init.OverSampling = UART_OVERSAMPLING_16;
  huart4.Init.OneBitSampling = UART_ONE_BIT_SAMPLE_DISABLE;
  huart4.Init.ClockPrescaler = UART_PRESCALER_DIV1;
  huart4.AdvancedInit.AdvFeatureInit = UART_ADVFEATURE_NO_INIT;
  if (HAL_UART_Init(&huart4) != HAL_OK)
  {
    Error_Handler();
  }
  if (HAL_UARTEx_SetTxFifoThreshold(&huart4, UART_TXFIFO_THRESHOLD_1_8) != HAL_OK)
  {
    Error_Handler();
  }
  if (HAL_UARTEx_SetRxFifoThreshold(&huart4, UART_RXFIFO_THRESHOLD_1_8) != HAL_OK)
  {
    Error_Handler();
  }
  if (HAL_UARTEx_DisableFifoMode(&huart4) != HAL_OK)
  {
    Error_Handler();
  }

}

static void MX_USB_OTG_FS_PCD_Init(void)
{

  hpcd_USB_OTG_FS.Instance = USB_OTG_FS;
  hpcd_USB_OTG_FS.Init.dev_endpoints = 9;
  hpcd_USB_OTG_FS.Init.speed = PCD_SPEED_FULL;
  hpcd_USB_OTG_FS.Init.dma_enable = DISABLE;
  hpcd_USB_OTG_FS.Init.phy_itface = PCD_PHY_EMBEDDED;
  hpcd_USB_OTG_FS.Init.Sof_enable = ENABLE;
  hpcd_USB_OTG_FS.Init.low_power_enable = DISABLE;
  hpcd_USB_OTG_FS.Init.lpm_enable = DISABLE;
  hpcd_USB_OTG_FS.Init.battery_charging_enable = ENABLE;
  hpcd_USB_OTG_FS.Init.vbus_sensing_enable = ENABLE;
  hpcd_USB_OTG_FS.Init.use_dedicated_ep1 = DISABLE;
  if (HAL_PCD_Init(&hpcd_USB_OTG_FS) != HAL_OK)
  {
    Error_Handler();
  }

}

/* FMC initialization function */
void MX_FMC_Init(void)
{

  FMC_SDRAM_TimingTypeDef SdramTiming = {0};

  /** Perform the SDRAM1 memory initialization sequence
  */
  hsdram1.Instance = FMC_SDRAM_DEVICE;
  /* hsdram1.Init */
  hsdram1.Init.SDBank = FMC_SDRAM_BANK1;
  hsdram1.Init.ColumnBitsNumber = FMC_SDRAM_COLUMN_BITS_NUM_8;
  hsdram1.Init.RowBitsNumber = FMC_SDRAM_ROW_BITS_NUM_12;
  hsdram1.Init.MemoryDataWidth = FMC_SDRAM_MEM_BUS_WIDTH_16;
  hsdram1.Init.InternalBankNumber = FMC_SDRAM_INTERN_BANKS_NUM_4;
  hsdram1.Init.CASLatency = FMC_SDRAM_CAS_LATENCY_1;
  hsdram1.Init.WriteProtection = FMC_SDRAM_WRITE_PROTECTION_DISABLE;
  hsdram1.Init.SDClockPeriod = FMC_SDRAM_CLOCK_DISABLE;
  hsdram1.Init.ReadBurst = FMC_SDRAM_RBURST_DISABLE;
  hsdram1.Init.ReadPipeDelay = FMC_SDRAM_RPIPE_DELAY_0;
  /* SdramTiming */
  SdramTiming.LoadToActiveDelay = 16;
  SdramTiming.ExitSelfRefreshDelay = 16;
  SdramTiming.SelfRefreshTime = 16;
  SdramTiming.RowCycleDelay = 16;
  SdramTiming.WriteRecoveryTime = 16;
  SdramTiming.RPDelay = 16;
  SdramTiming.RCDDelay = 16;

  if (HAL_SDRAM_Init(&hsdram1, &SdramTiming) != HAL_OK)
  {
    Error_Handler( );
  }

}

static void MX_GPIO_Init(void)
{
  GPIO_InitTypeDef GPIO_InitStruct = {0};

  /* GPIO Ports Clock Enable */
  __HAL_RCC_GPIOE_CLK_ENABLE();
  __HAL_RCC_GPIOC_CLK_ENABLE();
  __HAL_RCC_GPIOF_CLK_ENABLE();
  __HAL_RCC_GPIOH_CLK_ENABLE();
  __HAL_RCC_GPIOA_CLK_ENABLE();
  __HAL_RCC_GPIOB_CLK_ENABLE();
  __HAL_RCC_GPIOG_CLK_ENABLE();
  __HAL_RCC_GPIOD_CLK_ENABLE();

  /*Configure GPIO pin Output Level */
  HAL_GPIO_WritePin(GPIOC, OSC32_ENABLE_Pin|LCD_NCS_Pin|LCD_RST_Pin|OSC12M_EN_Pin, GPIO_PIN_SET);

  /*Configure GPIO pin Output Level */
  HAL_GPIO_WritePin(OSC_ENABLE_GPIO_Port, OSC_ENABLE_Pin, GPIO_PIN_SET);

  /*Configure GPIO pin Output Level */
  HAL_GPIO_WritePin(MCU_EXRST_GPIO_Port, MCU_EXRST_Pin, GPIO_PIN_SET);

  /*Configure GPIO pin Output Level */
  HAL_GPIO_WritePin(LCD_DC_GPIO_Port, LCD_DC_Pin, GPIO_PIN_RESET);

  /*Configure GPIO pin Output Level */
  HAL_GPIO_WritePin(GPIOB, LCD_SDCS_Pin|SR_NCLR_Pin|EEPROM_NWP_Pin|VDD33_ON_Pin
                          |VDD50_ON_Pin, GPIO_PIN_SET);

  /*Configure GPIO pin Output Level */
  HAL_GPIO_WritePin(GPIOD, LED2_Pin|LED3_Pin|UI_EN_Pin, GPIO_PIN_SET);

  /*Configure GPIO pin Output Level */
  HAL_GPIO_WritePin(GPIOG, LED0_Pin|LED1_Pin|UI_NCS2_Pin|UI_NCS1_Pin
                          |UI_NCS0_Pin, GPIO_PIN_SET);

  /*Configure GPIO pin Output Level */
  HAL_GPIO_WritePin(GPIOC, DAC_NSMT_Pin|DAC_FMT_Pin, GPIO_PIN_RESET);

  /*Configure GPIO pins : OSC32_ENABLE_Pin LCD_NCS_Pin LCD_RST_Pin OSC12M_EN_Pin */
  GPIO_InitStruct.Pin = OSC32_ENABLE_Pin|LCD_NCS_Pin|LCD_RST_Pin|OSC12M_EN_Pin;
  GPIO_InitStruct.Mode = GPIO_MODE_OUTPUT_OD;
  GPIO_InitStruct.Pull = GPIO_NOPULL;
  GPIO_InitStruct.Speed = GPIO_SPEED_FREQ_LOW;
  HAL_GPIO_Init(GPIOC, &GPIO_InitStruct);

  /*Configure GPIO pin : OSC_ENABLE_Pin */
  GPIO_InitStruct.Pin = OSC_ENABLE_Pin;
  GPIO_InitStruct.Mode = GPIO_MODE_OUTPUT_OD;
  GPIO_InitStruct.Pull = GPIO_NOPULL;
  GPIO_InitStruct.Speed = GPIO_SPEED_FREQ_LOW;
  HAL_GPIO_Init(OSC_ENABLE_GPIO_Port, &GPIO_InitStruct);

  /*Configure GPIO pin : MCU_EXRST_Pin */
  GPIO_InitStruct.Pin = MCU_EXRST_Pin;
  GPIO_InitStruct.Mode = GPIO_MODE_OUTPUT_OD;
  GPIO_InitStruct.Pull = GPIO_NOPULL;
  GPIO_InitStruct.Speed = GPIO_SPEED_FREQ_LOW;
  HAL_GPIO_Init(MCU_EXRST_GPIO_Port, &GPIO_InitStruct);

  /*Configure GPIO pin : LCD_DC_Pin */
  GPIO_InitStruct.Pin = LCD_DC_Pin;
  GPIO_InitStruct.Mode = GPIO_MODE_OUTPUT_PP;
  GPIO_InitStruct.Pull = GPIO_NOPULL;
  GPIO_InitStruct.Speed = GPIO_SPEED_FREQ_LOW;
  HAL_GPIO_Init(LCD_DC_GPIO_Port, &GPIO_InitStruct);

  /*Configure GPIO pins : LCD_SDCS_Pin SR_NCLR_Pin EEPROM_NWP_Pin VDD33_ON_Pin
                           VDD50_ON_Pin */
  GPIO_InitStruct.Pin = LCD_SDCS_Pin|SR_NCLR_Pin|EEPROM_NWP_Pin|VDD33_ON_Pin
                          |VDD50_ON_Pin;
  GPIO_InitStruct.Mode = GPIO_MODE_OUTPUT_OD;
  GPIO_InitStruct.Pull = GPIO_NOPULL;
  GPIO_InitStruct.Speed = GPIO_SPEED_FREQ_LOW;
  HAL_GPIO_Init(GPIOB, &GPIO_InitStruct);

  /*Configure GPIO pins : LED2_Pin LED3_Pin */
  GPIO_InitStruct.Pin = LED2_Pin|LED3_Pin;
  GPIO_InitStruct.Mode = GPIO_MODE_OUTPUT_PP;
  GPIO_InitStruct.Pull = GPIO_NOPULL;
  GPIO_InitStruct.Speed = GPIO_SPEED_FREQ_LOW;
  HAL_GPIO_Init(GPIOD, &GPIO_InitStruct);

  /*Configure GPIO pins : LED0_Pin LED1_Pin */
  GPIO_InitStruct.Pin = LED0_Pin|LED1_Pin;
  GPIO_InitStruct.Mode = GPIO_MODE_OUTPUT_PP;
  GPIO_InitStruct.Pull = GPIO_NOPULL;
  GPIO_InitStruct.Speed = GPIO_SPEED_FREQ_LOW;
  HAL_GPIO_Init(GPIOG, &GPIO_InitStruct);

  /*Configure GPIO pins : DAC_NSMT_Pin DAC_FMT_Pin */
  GPIO_InitStruct.Pin = DAC_NSMT_Pin|DAC_FMT_Pin;
  GPIO_InitStruct.Mode = GPIO_MODE_OUTPUT_PP;
  GPIO_InitStruct.Pull = GPIO_NOPULL;
  GPIO_InitStruct.Speed = GPIO_SPEED_FREQ_LOW;
  HAL_GPIO_Init(GPIOC, &GPIO_InitStruct);

  /*Configure GPIO pin : IOX_INT_Pin */
  GPIO_InitStruct.Pin = IOX_INT_Pin;
  GPIO_InitStruct.Mode = GPIO_MODE_IT_RISING;
  GPIO_InitStruct.Pull = GPIO_NOPULL;
  HAL_GPIO_Init(IOX_INT_GPIO_Port, &GPIO_InitStruct);

  /*Configure GPIO pin : UI_EN_Pin */
  GPIO_InitStruct.Pin = UI_EN_Pin;
  GPIO_InitStruct.Mode = GPIO_MODE_OUTPUT_OD;
  GPIO_InitStruct.Pull = GPIO_NOPULL;
  GPIO_InitStruct.Speed = GPIO_SPEED_FREQ_LOW;
  HAL_GPIO_Init(UI_EN_GPIO_Port, &GPIO_InitStruct);

  /*Configure GPIO pins : UI_NCS2_Pin UI_NCS1_Pin UI_NCS0_Pin */
  GPIO_InitStruct.Pin = UI_NCS2_Pin|UI_NCS1_Pin|UI_NCS0_Pin;
  GPIO_InitStruct.Mode = GPIO_MODE_OUTPUT_OD;
  GPIO_InitStruct.Pull = GPIO_NOPULL;
  GPIO_InitStruct.Speed = GPIO_SPEED_FREQ_LOW;
  HAL_GPIO_Init(GPIOG, &GPIO_InitStruct);

}

 /* MPU Configuration */

void MPU_Config(void)
{
  MPU_Region_InitTypeDef MPU_InitStruct = {0};

  /* Disables the MPU */
  HAL_MPU_Disable();

  /** Initializes and configures the Region and the memory to be protected
  */
  MPU_InitStruct.Enable = MPU_REGION_ENABLE;
  MPU_InitStruct.Number = MPU_REGION_NUMBER0;
  MPU_InitStruct.BaseAddress = 0x0;
  MPU_InitStruct.Size = MPU_REGION_SIZE_4GB;
  MPU_InitStruct.SubRegionDisable = 0x87;
  MPU_InitStruct.TypeExtField = MPU_TEX_LEVEL0;
  MPU_InitStruct.AccessPermission = MPU_REGION_NO_ACCESS;
  MPU_InitStruct.DisableExec = MPU_INSTRUCTION_ACCESS_DISABLE;
  MPU_InitStruct.IsShareable = MPU_ACCESS_SHAREABLE;
  MPU_InitStruct.IsCacheable = MPU_ACCESS_NOT_CACHEABLE;
  MPU_InitStruct.IsBufferable = MPU_ACCESS_NOT_BUFFERABLE;

  HAL_MPU_ConfigRegion(&MPU_InitStruct);
  /* Enables the MPU */
  HAL_MPU_Enable(MPU_PRIVILEGED_DEFAULT);

}

void Error_Handler(void)
{
  __disable_irq();
  while (1)
  {
  }
}
